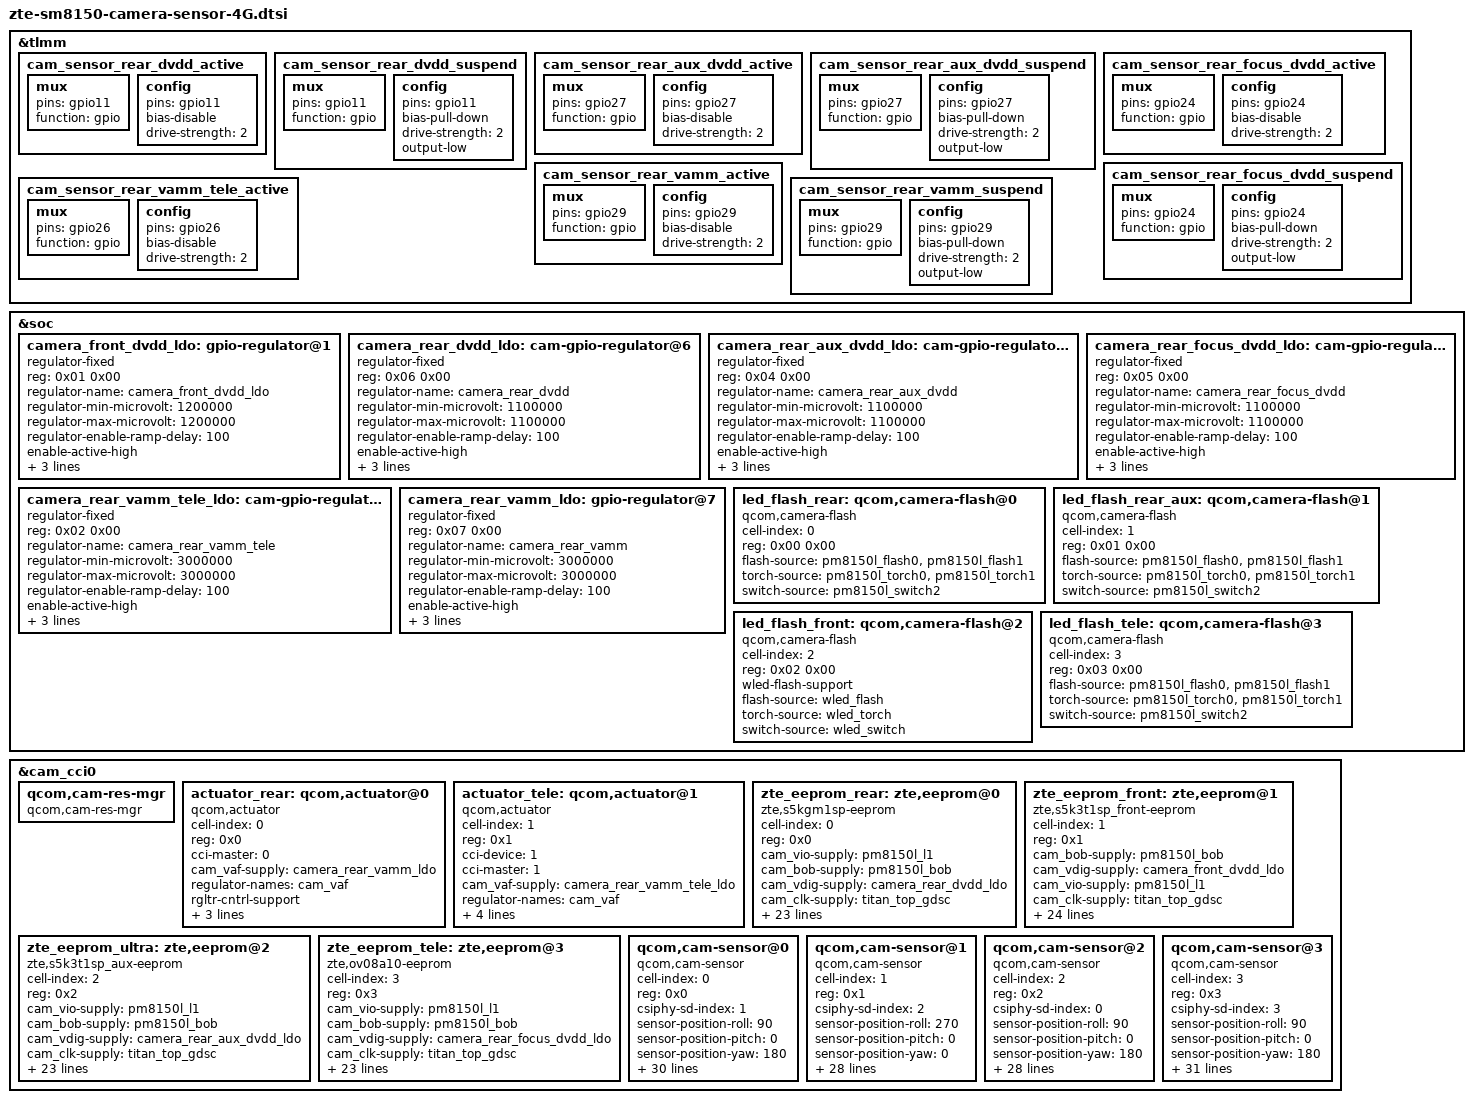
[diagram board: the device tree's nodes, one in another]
/*
 * Copyright (c) 2018, The Linux Foundation. All rights reserved.
 *
 * This program is free software; you can redistribute it and/or modify
 * it under the terms of the GNU General Public License version 2 and
 * only version 2 as published by the Free Software Foundation.
 *
 * This program is distributed in the hope that it will be useful,
 * but WITHOUT ANY WARRANTY; without even the implied warranty of
 * MERCHANTABILITY or FITNESS FOR A PARTICULAR PURPOSE.  See the
 * GNU General Public License for more details.
 */

 &tlmm{
		cam_sensor_rear_dvdd_active: cam_sensor_rear_dvdd_active {
			mux {
				pins = "gpio11";
				function = "gpio";
			};

			config {
				pins = "gpio11";
				bias-disable; /* NO PULL */
				drive-strength = <2>; /* 2 MA */
			};
		};

		cam_sensor_rear_dvdd_suspend: cam_sensor_rear_dvdd_suspend {
			mux {
				pins = "gpio11";
				function = "gpio";
			};

			config {
				pins = "gpio11";
				bias-pull-down; /* PULL DOWN */
				drive-strength = <2>; /* 2 MA */
				output-low;
			};
		};
		
		cam_sensor_rear_aux_dvdd_active: cam_sensor_rear_aux_dvdd_active {

			mux {
				pins = "gpio27";
				function = "gpio";
			};

			config {
				pins = "gpio27";
				bias-disable; /* No PULL */
				drive-strength = <2>; /* 2 MA */
			};
		};

		cam_sensor_rear_aux_dvdd_suspend: cam_sensor_rear_aux_dvdd_suspend {

			mux {
				pins = "gpio27";
				function = "gpio";
			};

			config {
				pins = "gpio27";
				bias-pull-down; /* PULL DOWN */
				drive-strength = <2>; /* 2 MA */
				output-low;
			};
		};

		cam_sensor_rear_focus_dvdd_active: cam_sensor_rear_focus_dvdd_active {
			mux {
				pins = "gpio24";
				function = "gpio";
			};

			config {
				pins = "gpio24";
				bias-disable; /* NO PULL */
				drive-strength = <2>; /* 2 MA */
			};
		};

		cam_sensor_rear_focus_dvdd_suspend: cam_sensor_rear_focus_dvdd_suspend {
			mux {
				pins = "gpio24";
				function = "gpio";
			};

			config {
				pins = "gpio24";
				bias-pull-down; /* PULL DOWN */
				drive-strength = <2>; /* 2 MA */
				output-low;
			};
		};

		cam_sensor_rear_vamm_tele_active: cam_sensor_rear_vamm_tele_active {
			mux {
				pins = "gpio26";
				function = "gpio";
			};

			config {
				pins = "gpio26";
				bias-disable; /* NO PULL */
				drive-strength = <2>; /* 2 MA */
			};
		};

		cam_sensor_rear_vamm_active: cam_sensor_rear_vamm_active {
			mux {
				pins = "gpio29";
				function = "gpio";
			};

			config {
				pins = "gpio29";
				bias-disable; /* NO PULL */
				drive-strength = <2>; /* 2 MA */
			};
		};

		cam_sensor_rear_vamm_suspend: cam_sensor_rear_vamm_suspend {
			mux {
				pins = "gpio29";
				function = "gpio";
			};

			config {
				pins = "gpio29";
				bias-pull-down; /* PULL DOWN */
				drive-strength = <2>; /* 2 MA */
				output-low;
			};
		};

 };

&soc {
	camera_front_dvdd_ldo: gpio-regulator@1 {
		compatible = "regulator-fixed";
		reg = <0x01 0x00>;
		regulator-name = "camera_front_dvdd_ldo";
		regulator-min-microvolt = <1200000>;
		regulator-max-microvolt = <1200000>;
		regulator-enable-ramp-delay = <100>;
		enable-active-high;
		gpio = <&pm8150l_gpios 4 0>;
		pinctrl-names = "camera_front_dvdd_default";
		pinctrl-0 = <&cam_sensor_eldo3_default>;
		vin-supply = <&pm8150_s4>;
	};

	camera_rear_dvdd_ldo: cam-gpio-regulator@6 {
		compatible = "regulator-fixed";
		reg = <0x06 0x00>;
		regulator-name = "camera_rear_dvdd";
		regulator-min-microvolt = <1100000>;
		regulator-max-microvolt = <1100000>;
		regulator-enable-ramp-delay = <100>;
		enable-active-high;
		gpio = <&tlmm 11 0>;
		pinctrl-names = "cam_rear_dvdd";
		pinctrl-0 = <&cam_sensor_rear_dvdd_active>;
		vin-supply = <&pm8150_s4>;
	};

	camera_rear_aux_dvdd_ldo: cam-gpio-regulator@4 {
		compatible = "regulator-fixed";
		reg = <0x04 0x00>;
		regulator-name = "camera_rear_aux_dvdd";
		regulator-min-microvolt = <1100000>;
		regulator-max-microvolt = <1100000>;
		regulator-enable-ramp-delay = <100>;
		enable-active-high;
		gpio = <&tlmm 27 0>;
		pinctrl-names = "cam_rear_aux_dvdd_default";
		pinctrl-0 = <&cam_sensor_rear_aux_dvdd_active>;
		vin-supply = <&pm8150_s4>;
	};

	camera_rear_focus_dvdd_ldo: cam-gpio-regulator@5 {
		compatible = "regulator-fixed";
		reg = <0x05 0x00>;
		regulator-name = "camera_rear_focus_dvdd";
		regulator-min-microvolt = <1100000>;
		regulator-max-microvolt = <1100000>;
		regulator-enable-ramp-delay = <100>;
		enable-active-high;
		gpio = <&tlmm 24 0>;
		pinctrl-names = "cam_rear_focus_dvdd_default";
		pinctrl-0 = <&cam_sensor_rear_focus_dvdd_active>;
		vin-supply = <&pm8150_s4>;
	};

	camera_rear_vamm_tele_ldo: cam-gpio-regulator@2 {
		compatible = "regulator-fixed";
		reg = <0x02 0x00>;
		regulator-name = "camera_rear_vamm_tele";
		regulator-min-microvolt = <3000000>;
		regulator-max-microvolt = <3000000>;
		regulator-enable-ramp-delay = <100>;
		enable-active-high;
		gpio = <&tlmm 26 0>;
		pinctrl-names = "cam_vamm";
		pinctrl-0 = <&cam_sensor_rear_vamm_tele_active>;
		vin-supply = <&pm8150l_bob>;
	};

	camera_rear_vamm_ldo: gpio-regulator@7 {
		compatible = "regulator-fixed";
		reg = <0x07 0x00>;
		regulator-name = "camera_rear_vamm";
		regulator-min-microvolt = <3000000>;
		regulator-max-microvolt = <3000000>;
		regulator-enable-ramp-delay = <100>;
		enable-active-high;
		gpio = <&tlmm 29 0>;
		pinctrl-names = "cam_vamm";
		pinctrl-0 = <&cam_sensor_rear_vamm_active>;
		vin-supply = <&pm8150l_bob>;
	};

	led_flash_rear: qcom,camera-flash@0 {
		cell-index = <0>;
		reg = <0x00 0x00>;
		compatible = "qcom,camera-flash";
		flash-source = <&pm8150l_flash0 &pm8150l_flash1>;
		torch-source = <&pm8150l_torch0 &pm8150l_torch1>;
		switch-source = <&pm8150l_switch2>;
		status = "ok";
	};

	led_flash_rear_aux: qcom,camera-flash@1 {
		cell-index = <1>;
		reg = <0x01 0x00>;
		compatible = "qcom,camera-flash";
		flash-source = <&pm8150l_flash0 &pm8150l_flash1>;
		torch-source = <&pm8150l_torch0 &pm8150l_torch1>;
		switch-source = <&pm8150l_switch2>;
		status = "ok";
	};

	led_flash_front: qcom,camera-flash@2 {
		cell-index = <2>;
		reg = <0x02 0x00>;
		compatible = "qcom,camera-flash";
		wled-flash-support;
		flash-source = <&wled_flash>;
		torch-source = <&wled_torch>;
		switch-source = <&wled_switch>;
		status = "ok";
	};

	led_flash_tele: qcom,camera-flash@3 {
		cell-index = <3>;
		reg = <0x03 0x00>;
		compatible = "qcom,camera-flash";
		flash-source = <&pm8150l_flash0 &pm8150l_flash1>;
		torch-source = <&pm8150l_torch0 &pm8150l_torch1>;
		switch-source = <&pm8150l_switch2>;
		status = "ok";
	};

	};

&cam_cci0 {
	qcom,cam-res-mgr {
		compatible = "qcom,cam-res-mgr";
		status = "ok";
	};

	actuator_rear: qcom,actuator@0 {
		cell-index = <0>;
		reg = <0x0>;
		compatible = "qcom,actuator";
		cci-master = <0>;
		cam_vaf-supply = <&camera_rear_vamm_ldo>;
		regulator-names = "cam_vaf";
		rgltr-cntrl-support;
		rgltr-min-voltage = <3000000>;
		rgltr-max-voltage = <3000000>;
		rgltr-load-current = <0>;
	};

	actuator_tele: qcom,actuator@1 {
		cell-index = <1>;
		reg = <0x1>;
		compatible = "qcom,actuator";
		cci-device=<1>;
		cci-master = <1>;
		cam_vaf-supply = <&camera_rear_vamm_tele_ldo>;
		regulator-names = "cam_vaf";
		rgltr-cntrl-support;
		rgltr-min-voltage = <3000000>;
		rgltr-max-voltage = <3000000>;
		rgltr-load-current = <0>;
	};

	zte_eeprom_rear: zte,eeprom@0 {
		cell-index = <0>;
		reg = <0x0>;
		compatible = "zte,s5kgm1sp-eeprom";
		cam_vio-supply = <&pm8150l_l1>;
		cam_bob-supply = <&pm8150l_bob>;
		cam_vdig-supply = <&camera_rear_dvdd_ldo>;
		cam_clk-supply = <&titan_top_gdsc>;
		regulator-names = "cam_vio", "cam_vdig",
			"cam_clk", "cam_bob";
		rgltr-cntrl-support;
		pwm-switch;
		rgltr-min-voltage = <0 1100000 0 3008000>;
		rgltr-max-voltage = <0 1100000 0 4000000>;
		rgltr-load-current = <0 0 0 2000000>;
		gpio-no-mux = <0>;
		pinctrl-names = "cam_default", "cam_suspend";
		pinctrl-0 = <&cam_sensor_mclk0_active
				&cam_sensor_active_rear>;
		pinctrl-1 = <&cam_sensor_mclk0_suspend
				&cam_sensor_suspend_rear>;
		gpios = <&tlmm 13 0>,
			<&tlmm 28 0>;
		gpio-reset = <1>;
		gpio-req-tbl-num = <0 1>;
		gpio-req-tbl-flags = <1 0>;
		gpio-req-tbl-label = "CAMIF_MCLK0",
					"CAM_RESET0";
		sensor-position = <0>;
		sensor-mode = <0>;
		cci-master = <0>;
		status = "ok";
		clocks = <&clock_camcc CAM_CC_MCLK0_CLK>;
		clock-names = "cam_clk";
		clock-cntl-level = "turbo";
		clock-rates = <24000000>;
	};

	zte_eeprom_front: zte,eeprom@1 {
		cell-index = <1>;
		reg = <0x1>;
		compatible = "zte,s5k3t1sp_front-eeprom";
		cam_bob-supply = <&pm8150l_bob>;
		cam_vdig-supply = <&camera_front_dvdd_ldo>;
		cam_vio-supply=<&pm8150l_l1>;
		cam_clk-supply = <&titan_top_gdsc>;
		regulator-names = "cam_vdig",
			"cam_clk", "cam_bob","cam_vio";
		rgltr-cntrl-support;
		pwm-switch;
		rgltr-min-voltage = < 1200000 0 3008000 0>;
		rgltr-max-voltage = < 1200000 0 4000000 0>;
		rgltr-load-current = <0 0 2000000 0>;
		gpio-no-mux = <0>;
		pinctrl-names = "cam_default", "cam_suspend";
		pinctrl-0 = <&cam_sensor_mclk2_active
				 &cam_sensor_active_front>;
		pinctrl-1 = <&cam_sensor_mclk2_suspend
				 &cam_sensor_suspend_front>;
		gpios = <&tlmm 15 0>,
			<&tlmm 12 0>;
		gpio-reset = <1>;
		gpio-req-tbl-num = <0 1>;
		gpio-req-tbl-flags = <1 0>;
		gpio-req-tbl-label = "CAMIF_MCLK2",
					"CAM_RESET2";
		sensor-position = <1>;
		sensor-mode = <0>;
		cci-device=<1>;
		cci-master = <0>;
		status = "ok";
		clocks = <&clock_camcc CAM_CC_MCLK2_CLK>;
		clock-names = "cam_clk";
		clock-cntl-level = "turbo";
		clock-rates = <24000000>;
	};

	zte_eeprom_ultra: zte,eeprom@2 {
		cell-index = <2>;
		reg = <0x2>;
		compatible = "zte,s5k3t1sp_aux-eeprom";
		cam_vio-supply = <&pm8150l_l1>;
		cam_bob-supply = <&pm8150l_bob>;
		cam_vdig-supply = <&camera_rear_aux_dvdd_ldo>;
		cam_clk-supply = <&titan_top_gdsc>;
		regulator-names = "cam_vio", "cam_vdig",
			"cam_clk", "cam_bob";
		rgltr-cntrl-support;
		pwm-switch;
		rgltr-min-voltage = <0 1100000 0 3008000>;
		rgltr-max-voltage = <0 1100000 0 4000000>;
		rgltr-load-current = <0 0 0 2000000>;
		gpio-no-mux = <0>;
		pinctrl-names = "cam_default", "cam_suspend";
		pinctrl-0 = <&cam_sensor_mclk1_active
				&cam_sensor_active_rear_aux>;
		pinctrl-1 = <&cam_sensor_mclk1_suspend
				&cam_sensor_suspend_rear_aux>;
		gpios = <&tlmm 14 0>,
			<&tlmm 30 0>;
		gpio-reset = <1>;
		gpio-req-tbl-num = <0 1>;
		gpio-req-tbl-flags = <1 0>;
		gpio-req-tbl-label = "CAMIF_MCLK1",
					"CAM_RESET1";
		sensor-position = <0>;
		sensor-mode = <0>;
		cci-master = <1>;
		status = "ok";
		clocks = <&clock_camcc CAM_CC_MCLK1_CLK>;
		clock-names = "cam_clk";
		clock-cntl-level = "turbo";
		clock-rates = <24000000>;
	};

	zte_eeprom_tele: zte,eeprom@3 {
		cell-index = <3>;
		compatible = "zte,ov08a10-eeprom";
		reg = <0x3>;
		cam_vio-supply = <&pm8150l_l1>;
		cam_bob-supply = <&pm8150l_bob>;
		cam_vdig-supply = <&camera_rear_focus_dvdd_ldo>;
		cam_clk-supply = <&titan_top_gdsc>;
		regulator-names = "cam_vio", "cam_vdig",
			"cam_clk", "cam_bob";
		rgltr-cntrl-support;
		pwm-switch;
		rgltr-min-voltage = <0 1100000 0 3008000>;
		rgltr-max-voltage = <0 1100000 0 4000000>;
		rgltr-load-current = <0 0 0 2000000>;
		gpio-no-mux = <0>;
		pinctrl-names = "cam_default", "cam_suspend";
		pinctrl-0 = <&cam_sensor_mclk3_active
				&cam_sensor_active_iris>;
		pinctrl-1 = <&cam_sensor_mclk3_suspend
				&cam_sensor_suspend_iris>;
		gpios = <&tlmm 16 0>,
			<&tlmm 23 0>;
		gpio-reset = <1>;
		gpio-req-tbl-num = <0 1>;
		gpio-req-tbl-flags = <1 0>;
		gpio-req-tbl-label = "CAMIF_MCLK3",
					"CAM_RESET3";
		sensor-mode = <0>;
		cci-device=<1>;
		cci-master = <1>;
		status = "ok";
		clocks = <&clock_camcc CAM_CC_MCLK3_CLK>;
		clock-names = "cam_clk";
		clock-cntl-level = "turbo";
		clock-rates = <24000000>;
	};

//main sensor
	qcom,cam-sensor@0 {
		cell-index = <0>;
		compatible = "qcom,cam-sensor";
		reg = <0x0>;
		csiphy-sd-index = <1>;
		sensor-position-roll = <90>;
		sensor-position-pitch = <0>;
		sensor-position-yaw = <180>;
		led-flash-src = <&led_flash_rear>;
		actuator-src = <&actuator_rear>;
		eeprom-src = <&zte_eeprom_rear>;
		cam_vio-supply = <&pm8150l_l1>;
		cam_bob-supply = <&pm8150l_bob>;
		cam_vdig-supply = <&camera_rear_dvdd_ldo>;
		cam_vaf-supply = <&camera_rear_vamm_ldo>;
		cam_clk-supply = <&titan_top_gdsc>;
		regulator-names = "cam_vio", "cam_vdig",
			"cam_clk", "cam_bob", "cam_vaf";
		rgltr-cntrl-support;
		pwm-switch;
		rgltr-min-voltage = <0 1100000 0 3008000 3000000>;
		rgltr-max-voltage = <0 1100000 0 4000000 3000000>;
		rgltr-load-current = <0 0 0 2000000 0>;
		gpio-no-mux = <0>;
		pinctrl-names = "cam_default", "cam_suspend";
		pinctrl-0 = <&cam_sensor_mclk0_active
				&cam_sensor_active_rear>;
		pinctrl-1 = <&cam_sensor_mclk0_suspend
				&cam_sensor_suspend_rear>;
		gpios = <&tlmm 13 0>,
			<&tlmm 28 0>;
		gpio-reset = <1>;
		gpio-req-tbl-num = <0 1>;
		gpio-req-tbl-flags = <1 0>;
		gpio-req-tbl-label = "CAMIF_MCLK0",
					"CAM_RESET0";
		sensor-mode = <0>;
		cci-master = <0>;
		status = "ok";
		clocks = <&clock_camcc CAM_CC_MCLK0_CLK>;
		clock-names = "cam_clk";
		clock-cntl-level = "turbo";
		clock-rates = <24000000>;
	};

//front sensor
	qcom,cam-sensor@1 {
		cell-index = <1>;
		compatible = "qcom,cam-sensor";
		reg = <0x1>;
		csiphy-sd-index = <2>;
		sensor-position-roll = <270>;
		sensor-position-pitch = <0>;
		sensor-position-yaw = <0>;
		eeprom-src = <&zte_eeprom_front>;
		cam_bob-supply = <&pm8150l_bob>;
		cam_vdig-supply = <&camera_front_dvdd_ldo>;
		cam_vio-supply=<&pm8150l_l1>;
		cam_clk-supply = <&titan_top_gdsc>;
		regulator-names = "cam_vdig",
			"cam_clk", "cam_bob","cam_vio";
		rgltr-cntrl-support;
		pwm-switch;
		rgltr-min-voltage = < 1200000  0 3008000 0>;
		rgltr-max-voltage = < 1200000  0 4000000 0>;
		rgltr-load-current = <0  0 2000000 0>;
		gpio-no-mux = <0>;
		pinctrl-names = "cam_default", "cam_suspend";
		pinctrl-0 = <&cam_sensor_mclk2_active
				 &cam_sensor_active_front>;
		pinctrl-1 = <&cam_sensor_mclk2_suspend
				 &cam_sensor_suspend_front>;
		gpios = <&tlmm 15 0>,
			<&tlmm 12 0>;
		gpio-reset = <1>;
		gpio-req-tbl-num = <0 1>;
		gpio-req-tbl-flags = <1 0>;
		gpio-req-tbl-label = "CAMIF_MCLK2",
					"CAM_RESET2";
		sensor-mode = <0>;
		cci-device=<1>;
		cci-master = <0>;
		status = "ok";
		clocks = <&clock_camcc CAM_CC_MCLK2_CLK>;
		clock-names = "cam_clk";
		clock-cntl-level = "turbo";
		clock-rates = <24000000>;
	};

//ultra wide sensor
	qcom,cam-sensor@2 {
		cell-index = <2>;
		compatible = "qcom,cam-sensor";
		reg = <0x2>;
		csiphy-sd-index = <0>;
		sensor-position-roll = <90>;
		sensor-position-pitch = <0>;
		sensor-position-yaw = <180>;
		led-flash-src = <&led_flash_rear_aux>;
		eeprom-src = <&zte_eeprom_ultra>;
		cam_vio-supply = <&pm8150l_l1>;
		cam_bob-supply = <&pm8150l_bob>;
		cam_vdig-supply = <&camera_rear_aux_dvdd_ldo>;
		cam_clk-supply = <&titan_top_gdsc>;
		regulator-names = "cam_vio", "cam_vdig",
			"cam_clk", "cam_bob";
		rgltr-cntrl-support;
		pwm-switch;
		rgltr-min-voltage = <0 1100000 0 3008000>;
		rgltr-max-voltage = <0 1100000 0 4000000>;
		rgltr-load-current = <0 0 0 2000000>;
		gpio-no-mux = <0>;
		pinctrl-names = "cam_default", "cam_suspend";
		pinctrl-0 = <&cam_sensor_mclk1_active
				&cam_sensor_active_rear_aux>;
		pinctrl-1 = <&cam_sensor_mclk1_suspend
				&cam_sensor_suspend_rear_aux>;
		gpios = <&tlmm 14 0>,
			<&tlmm 30 0>;
		gpio-reset = <1>;
		gpio-req-tbl-num = <0 1>;
		gpio-req-tbl-flags = <1 0>;
		gpio-req-tbl-label = "CAMIF_MCLK1",
					"CAM_RESET1";
		sensor-mode = <0>;
		cci-master = <1>;
		status = "ok";
		clocks = <&clock_camcc CAM_CC_MCLK1_CLK>;
		clock-names = "cam_clk";
		clock-cntl-level = "turbo";
		clock-rates = <24000000>;
	};

// tele sensor
	qcom,cam-sensor@3 {
		cell-index = <3>;
		compatible = "qcom,cam-sensor";
		reg = <0x3>;
		csiphy-sd-index = <3>;
		sensor-position-roll = <90>;
		sensor-position-pitch = <0>;
		sensor-position-yaw = <180>;
		actuator-src = <&actuator_tele>;
		led-flash-src = <&led_flash_tele>;
		eeprom-src = <&zte_eeprom_tele>;
		cam_vio-supply = <&pm8150l_l1>;
		cam_bob-supply = <&pm8150l_bob>;
		cam_vdig-supply = <&camera_rear_focus_dvdd_ldo>;
		cam_vaf-supply = <&camera_rear_vamm_tele_ldo>;
		cam_clk-supply = <&titan_top_gdsc>;
		regulator-names = "cam_vio", "cam_vdig",
			"cam_clk", "cam_bob", "cam_vaf";
		rgltr-cntrl-support;
		pwm-switch;
		rgltr-min-voltage = <0 1100000 0 3008000 3000000>;
		rgltr-max-voltage = <0 1100000 0 4000000 3000000>;
		rgltr-load-current = <0 0 0 2000000 0>;
		gpio-no-mux = <0>;
		pinctrl-names = "cam_default", "cam_suspend";
		pinctrl-0 = <&cam_sensor_mclk3_active
				&cam_sensor_active_iris>;
		pinctrl-1 = <&cam_sensor_mclk3_suspend
				&cam_sensor_suspend_iris>;
		gpios = <&tlmm 16 0>,
			<&tlmm 23 0>;
		gpio-reset = <1>;
		gpio-req-tbl-num = <0 1>;
		gpio-req-tbl-flags = <1 0>;
		gpio-req-tbl-label = "CAMIF_MCLK3",
					"CAM_RESET3";
		sensor-mode = <0>;
		cci-device=<1>;
		cci-master = <1>;
		status = "ok";
		clocks = <&clock_camcc CAM_CC_MCLK3_CLK>;
		clock-names = "cam_clk";
		clock-cntl-level = "turbo";
		clock-rates = <24000000>;
	};
};

